# platform_designer_hps_system_hps_0_hps register map
Vendor: default_vendor.com; File version: 0.0
Registers are 32-bit, read-write, reset 0x0 unless marked. A register's access mark holds for its fields unless they carry their own. Offsets are from the block's base; [hi:lo] are bit positions; 'fields as' and 'values as' point back to an identical list.

## l3regs — Registers to control L3 interconnect settings
Base 0xFF800000
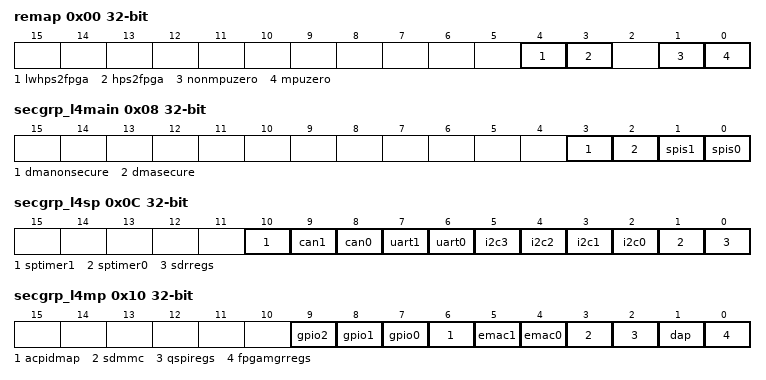
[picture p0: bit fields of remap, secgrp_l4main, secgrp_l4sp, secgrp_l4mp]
0x00 remap wo — The L3 interconnect has separate address maps for the various L3 Masters. Generally, the addresses are the same for most masters. However, the sparse interconnect of the L3 switch causes some masters to have holes in their memory maps. The remap bits are not mutually exclusive. Each bit can be set independently and in combinations. Priority for the bits is determined by the bit offset: lower offset bits take precedence over higher offset bits.
  [4] lwhps2fpga — Controls whether the Lightweight HPS2FPGA AXI Bridge is visible to L3 masters or not.
    0=invisible; 1=visible
  [3] hps2fpga — Controls whether the HPS2FPGA AXI Bridge is visible to L3 masters or not.
    0=invisible; 1=visible
  [1] nonmpuzero — Controls whether address 0x0 for the non-MPU L3 masters is mapped to the SDRAM or On-chip RAM. This field only has an effect on the non-MPU L3 masters. The non-MPU L3 masters are the DMA controllers (standalone and those built-in to peripherals), the FPGA2HPS AXI Bridge, and the DAP.
    0=sdram; 1=ocram
  [0] mpuzero — Controls whether address 0x0 for the MPU L3 master is mapped to the Boot ROM or On-chip RAM. This field only has an effect on the MPU L3 master.
    0=bootrom; 1=ocram
0x08 secgrp_l4main wo — Controls security settings for L4 Main peripherals.
  [all] fields
    0=secure; 1=nonsecure
  [3] dmanonsecure — Controls whether secure or non-secure masters can access the DMA Non-secure slave.
  [2] dmasecure — Controls whether secure or non-secure masters can access the DMA Secure slave.
  [1] spis1 — Controls whether secure or non-secure masters can access the SPI Slave 1 slave.
  [0] spis0 — Controls whether secure or non-secure masters can access the SPI Slave 0 slave.
0x0C secgrp_l4sp wo — Controls security settings for L4 SP peripherals.
  [all] fields
    0=secure; 1=nonsecure
  [10] sptimer1 — Controls whether secure or non-secure masters can access the SP Timer 1 slave.
  [9] can1 — Controls whether secure or non-secure masters can access the CAN 1 slave.
  [8] can0 — Controls whether secure or non-secure masters can access the CAN 0 slave.
  [7] uart1 — Controls whether secure or non-secure masters can access the UART 1 slave.
  [6] uart0 — Controls whether secure or non-secure masters can access the UART 0 slave.
  [5] i2c3 — Controls whether secure or non-secure masters can access the I2C3 (EMAC 1) slave.
  [4] i2c2 — Controls whether secure or non-secure masters can access the I2C2 (EMAC 0) slave.
  [3] i2c1 — Controls whether secure or non-secure masters can access the I2C1 slave.
  [2] i2c0 — Controls whether secure or non-secure masters can access the I2C0 slave.
  [1] sptimer0 — Controls whether secure or non-secure masters can access the SP Timer 0 slave.
  [0] sdrregs — Controls whether secure or non-secure masters can access the SDRAM Registers slave.
0x10 secgrp_l4mp wo — Controls security settings for L4 MP peripherals.
  [all] fields
    0=secure; 1=nonsecure
  [9] gpio2 — Controls whether secure or non-secure masters can access the GPIO 2 slave.
  [8] gpio1 — Controls whether secure or non-secure masters can access the GPIO 1 slave.
  [7] gpio0 — Controls whether secure or non-secure masters can access the GPIO 0 slave.
  [6] acpidmap — Controls whether secure or non-secure masters can access the ACP ID Mapper slave.
  [5] emac1 — Controls whether secure or non-secure masters can access the EMAC 1 slave.
  [4] emac0 — Controls whether secure or non-secure masters can access the EMAC 0 slave.
  [3] sdmmc — Controls whether secure or non-secure masters can access the SDMMC slave.
  [2] qspiregs — Controls whether secure or non-secure masters can access the QSPI Registers slave.
  [1] dap — Controls whether secure or non-secure masters can access the DAP slave.
  [0] fpgamgrregs — Controls whether secure or non-secure masters can access the FPGA Manager Register slave.
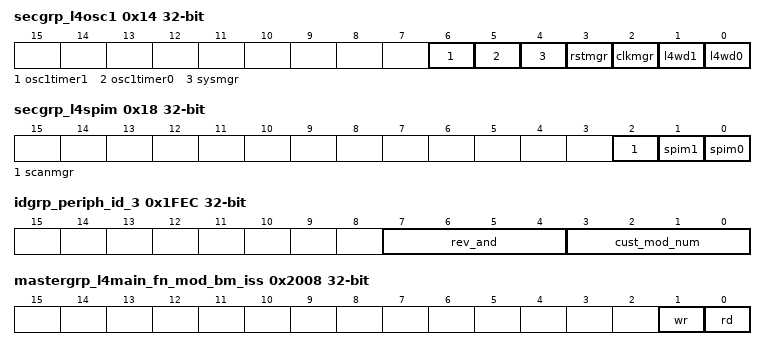
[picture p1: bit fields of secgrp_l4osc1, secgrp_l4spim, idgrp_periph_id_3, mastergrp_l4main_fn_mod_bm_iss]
0x14 secgrp_l4osc1 wo — Controls security settings for L4 OSC1 peripherals.
  [all] fields
    0=secure; 1=nonsecure
  [6] osc1timer1 — Controls whether secure or non-secure masters can access the OSC1 Timer 1 slave.
  [5] osc1timer0 — Controls whether secure or non-secure masters can access the OSC1 Timer 0 slave.
  [4] sysmgr — Controls whether secure or non-secure masters can access the System Manager slave.
  [3] rstmgr — Controls whether secure or non-secure masters can access the Reset Manager slave.
  [2] clkmgr — Controls whether secure or non-secure masters can access the Clock Manager slave.
  [1] l4wd1 — Controls whether secure or non-secure masters can access the L4 Watchdog Timer 0 slave.
  [0] l4wd0 — Controls whether secure or non-secure masters can access the L4 Watchdog Timer 0 slave.
0x18 secgrp_l4spim wo — Controls security settings for L4 SPIM peripherals.
  [all] fields
    0=secure; 1=nonsecure
  [2] scanmgr — Controls whether secure or non-secure masters can access the Scan Manager slave.
  [1] spim1 — Controls whether secure or non-secure masters can access the SPI Master 1 slave.
  [0] spim0 — Controls whether secure or non-secure masters can access the SPI Master 0 slave.
0x1C secgrp_stm wo — Controls security settings for STM peripheral.
  [0] s — Controls whether secure or non-secure masters can access the STM slave.
    0=secure; 1=nonsecure
0x20 secgrp_lwhps2fpgaregs wo — Controls security settings for LWHPS2FPGA AXI Bridge Registers peripheral.
  [0] s — Controls whether secure or non-secure masters can access the LWHPS2FPGA AXI Bridge Registers slave.
    0=secure; 1=nonsecure
0x28 secgrp_usb1 wo — Controls security settings for USB1 Registers peripheral.
  [0] s — Controls whether secure or non-secure masters can access the USB1 Registers slave.
    0=secure; 1=nonsecure
0x2C secgrp_nanddata wo — Controls security settings for NAND Flash Controller Data peripheral.
  [0] s — Controls whether secure or non-secure masters can access the NAND Flash Controller Data slave.
    0=secure; 1=nonsecure
0x80 secgrp_usb0 wo — Controls security settings for USB0 Registers peripheral.
  [0] s — Controls whether secure or non-secure masters can access the USB0 Registers slave.
    0=secure; 1=nonsecure
0x84 secgrp_nandregs wo — Controls security settings for NAND Flash Controller Registers peripheral.
  [0] s — Controls whether secure or non-secure masters can access the NAND Flash Controller Registers slave.
    0=secure; 1=nonsecure
0x88 secgrp_qspidata wo — Controls security settings for QSPI Flash Controller Data peripheral.
  [0] s — Controls whether secure or non-secure masters can access the QSPI Flash Controller Data slave.
    0=secure; 1=nonsecure
0x8C secgrp_fpgamgrdata wo — Controls security settings for FPGA Manager Data peripheral.
  [0] s — Controls whether secure or non-secure masters can access the FPGA Manager Data slave.
    0=secure; 1=nonsecure
0x90 secgrp_hps2fpgaregs wo — Controls security settings for HPS2FPGA AXI Bridge Registers peripheral.
  [0] s — Controls whether secure or non-secure masters can access the HPS2FPGA AXI Bridge Registers slave.
    0=secure; 1=nonsecure
0x94 secgrp_acp wo — Controls security settings for MPU ACP peripheral.
  [0] s — Controls whether secure or non-secure masters can access the MPU ACP slave.
    0=secure; 1=nonsecure
0x98 secgrp_rom wo — Controls security settings for ROM peripheral.
  [0] s — Controls whether secure or non-secure masters can access the ROM slave.
    0=secure; 1=nonsecure
0x9C secgrp_ocram wo — Controls security settings for On-chip RAM peripheral.
  [0] s — Controls whether secure or non-secure masters can access the On-chip RAM slave.
    0=secure; 1=nonsecure
0xA0 secgrp_sdrdata wo — Controls security settings for SDRAM Data peripheral.
  [0] s — Controls whether secure or non-secure masters can access the SDRAM Data slave.
    0=secure; 1=nonsecure
0x1FD0 idgrp_periph_id_4 ro reset 0x4 — JEP106 continuation code
  [7:0] periph_id_4
0x1FE0 idgrp_periph_id_0 ro reset 0x1 — Peripheral ID0
  [7:0] pn7to0 — Part Number [7:0]
0x1FE4 idgrp_periph_id_1 ro reset 0xB3 — Peripheral ID1
  [7:0] jep3to0_pn11to8 — JEP106[3:0], Part Number [11:8]
0x1FE8 idgrp_periph_id_2 ro reset 0x6B — Peripheral ID2
  [7:0] rev_jepcode_jep6to4 — Revision, JEP106 code flag, JEP106[6:4]
0x1FEC idgrp_periph_id_3 ro — Peripheral ID3
  [7:4] rev_and — Revision
  [3:0] cust_mod_num — Customer Model Number
0x1FF0 idgrp_comp_id_0 ro reset 0xD — Component ID0
  [7:0] preamble
0x1FF4 idgrp_comp_id_1 ro reset 0xF0 — Component ID1
  [7:0] genipcompcls_preamble — Generic IP component class, Preamble
0x1FF8 idgrp_comp_id_2 ro reset 0x5 — Component ID2
  [7:0] preamble
0x1FFC idgrp_comp_id_3 ro reset 0xB1 — Component ID3
  [7:0] preamble
0x2008 mastergrp_l4main_fn_mod_bm_iss — Sets the issuing capability of the preceding switch arbitration scheme to multiple or single outstanding transactions.
  [1] wr
    0=multiple; 1=single
  [0] rd
    0=multiple; 1=single
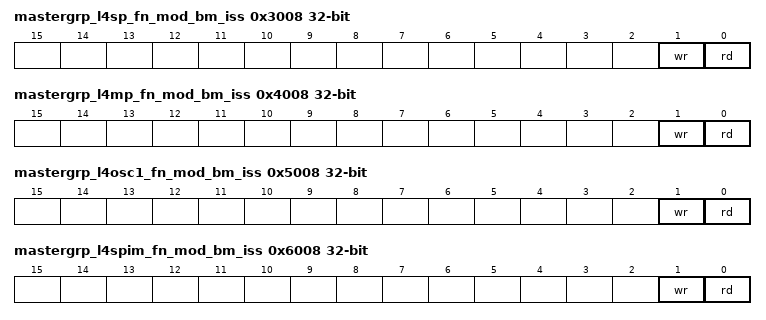
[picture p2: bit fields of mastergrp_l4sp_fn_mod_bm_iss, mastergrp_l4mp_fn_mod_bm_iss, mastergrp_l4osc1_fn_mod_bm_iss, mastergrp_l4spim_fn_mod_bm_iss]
0x3008 mastergrp_l4sp_fn_mod_bm_iss — Sets the issuing capability of the preceding switch arbitration scheme to multiple or single outstanding transactions.
  [1] wr
    0=multiple; 1=single
  [0] rd
    0=multiple; 1=single
0x4008 mastergrp_l4mp_fn_mod_bm_iss — Sets the issuing capability of the preceding switch arbitration scheme to multiple or single outstanding transactions.
  [1] wr
    0=multiple; 1=single
  [0] rd
    0=multiple; 1=single
0x5008 mastergrp_l4osc1_fn_mod_bm_iss — Sets the issuing capability of the preceding switch arbitration scheme to multiple or single outstanding transactions.
  [1] wr
    0=multiple; 1=single
  [0] rd
    0=multiple; 1=single
0x6008 mastergrp_l4spim_fn_mod_bm_iss — Sets the issuing capability of the preceding switch arbitration scheme to multiple or single outstanding transactions.
  [1] wr
    0=multiple; 1=single
  [0] rd
    0=multiple; 1=single
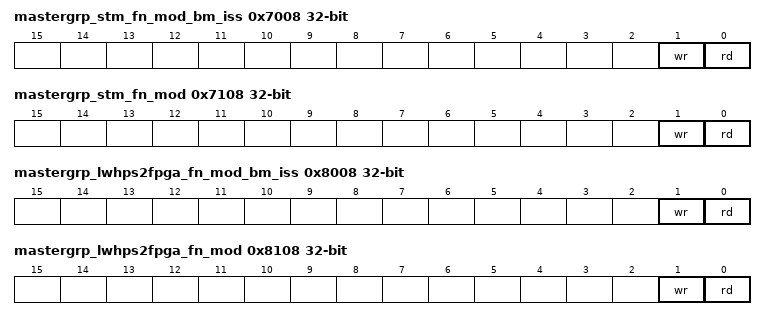
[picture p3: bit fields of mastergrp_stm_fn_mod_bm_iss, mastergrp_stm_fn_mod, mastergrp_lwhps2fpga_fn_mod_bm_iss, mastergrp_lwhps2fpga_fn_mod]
0x7008 mastergrp_stm_fn_mod_bm_iss — Sets the issuing capability of the preceding switch arbitration scheme to multiple or single outstanding transactions.
  [1] wr
    0=multiple; 1=single
  [0] rd
    0=multiple; 1=single
0x7108 mastergrp_stm_fn_mod — Sets the block issuing capability to multiple or single outstanding transactions.
  [1] wr
    0=multiple; 1=single
  [0] rd
    0=multiple; 1=single
0x8008 mastergrp_lwhps2fpga_fn_mod_bm_iss — Sets the issuing capability of the preceding switch arbitration scheme to multiple or single outstanding transactions.
  [1] wr
    0=multiple; 1=single
  [0] rd
    0=multiple; 1=single
0x8108 mastergrp_lwhps2fpga_fn_mod — Sets the block issuing capability to multiple or single outstanding transactions.
  [1] wr
    0=multiple; 1=single
  [0] rd
    0=multiple; 1=single
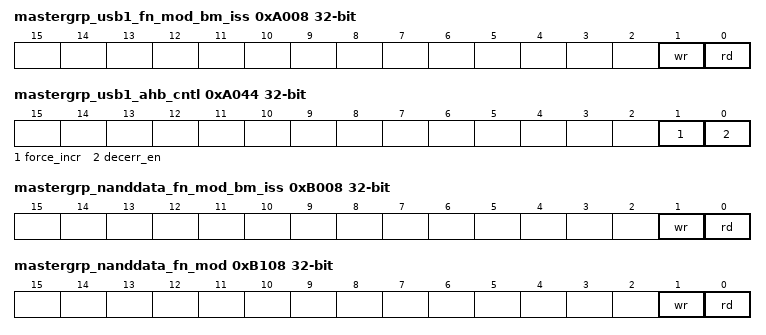
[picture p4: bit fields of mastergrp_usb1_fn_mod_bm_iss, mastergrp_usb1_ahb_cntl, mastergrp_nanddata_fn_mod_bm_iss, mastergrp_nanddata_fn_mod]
0xA008 mastergrp_usb1_fn_mod_bm_iss — Sets the issuing capability of the preceding switch arbitration scheme to multiple or single outstanding transactions.
  [1] wr
    0=multiple; 1=single
  [0] rd
    0=multiple; 1=single
0xA044 mastergrp_usb1_ahb_cntl — Sets the block issuing capability to one outstanding transaction.
  [1] force_incr
    0=disable; 1=enable
  [0] decerr_en
    0=disable; 1=enable
0xB008 mastergrp_nanddata_fn_mod_bm_iss — Sets the issuing capability of the preceding switch arbitration scheme to multiple or single outstanding transactions.
  [1] wr
    0=multiple; 1=single
  [0] rd
    0=multiple; 1=single
0xB108 mastergrp_nanddata_fn_mod — Sets the block issuing capability to multiple or single outstanding transactions.
  [1] wr
    0=multiple; 1=single
  [0] rd
    0=multiple; 1=single
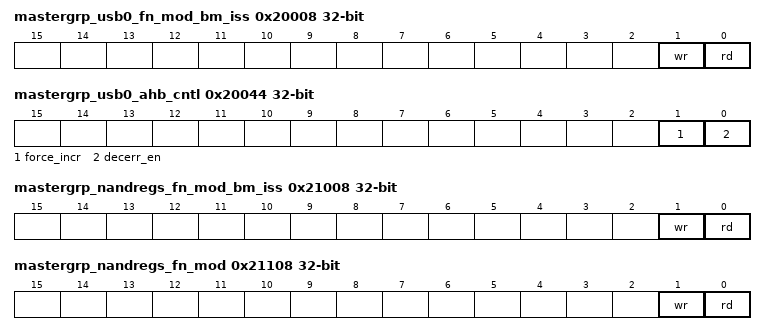
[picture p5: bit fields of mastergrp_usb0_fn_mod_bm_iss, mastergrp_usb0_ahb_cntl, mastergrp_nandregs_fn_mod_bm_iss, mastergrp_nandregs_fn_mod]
0x20008 mastergrp_usb0_fn_mod_bm_iss — Sets the issuing capability of the preceding switch arbitration scheme to multiple or single outstanding transactions.
  [1] wr
    0=multiple; 1=single
  [0] rd
    0=multiple; 1=single
0x20044 mastergrp_usb0_ahb_cntl — Sets the block issuing capability to one outstanding transaction.
  fields as mastergrp_usb1_ahb_cntl
0x21008 mastergrp_nandregs_fn_mod_bm_iss — Sets the issuing capability of the preceding switch arbitration scheme to multiple or single outstanding transactions.
  [1] wr
    0=multiple; 1=single
  [0] rd
    0=multiple; 1=single
0x21108 mastergrp_nandregs_fn_mod — Sets the block issuing capability to multiple or single outstanding transactions.
  [1] wr
    0=multiple; 1=single
  [0] rd
    0=multiple; 1=single
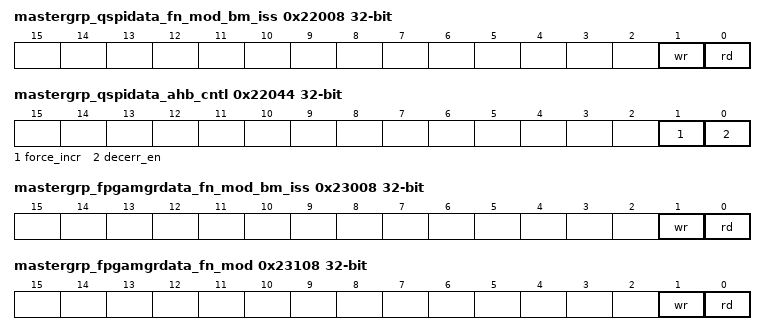
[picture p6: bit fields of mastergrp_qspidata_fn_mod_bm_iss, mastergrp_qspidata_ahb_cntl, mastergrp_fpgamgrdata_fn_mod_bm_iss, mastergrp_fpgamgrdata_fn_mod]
0x22008 mastergrp_qspidata_fn_mod_bm_iss — Sets the issuing capability of the preceding switch arbitration scheme to multiple or single outstanding transactions.
  [1] wr
    0=multiple; 1=single
  [0] rd
    0=multiple; 1=single
0x22044 mastergrp_qspidata_ahb_cntl — Sets the block issuing capability to one outstanding transaction.
  fields as mastergrp_usb1_ahb_cntl
0x23008 mastergrp_fpgamgrdata_fn_mod_bm_iss — Sets the issuing capability of the preceding switch arbitration scheme to multiple or single outstanding transactions.
  [1] wr
    0=multiple; 1=single
  [0] rd
    0=multiple; 1=single
0x23040 mastergrp_fpgamgrdata_wr_tidemark reset 0x4 — Controls the release of the transaction in the write data FIFO.
  [3:0] level — Stalls the transaction in the write data FIFO until the number of occupied slots in the write data FIFO exceeds the level. Note that the transaction is released before this level is achieved if the network receives the WLAST beat or the write FIFO becomes full.
0x23108 mastergrp_fpgamgrdata_fn_mod — Sets the block issuing capability to multiple or single outstanding transactions.
  [1] wr
    0=multiple; 1=single
  [0] rd
    0=multiple; 1=single
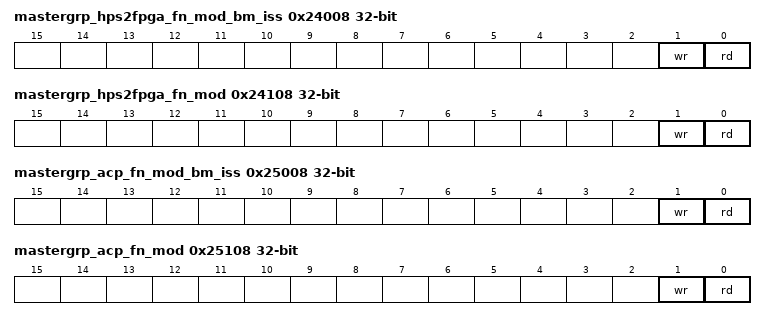
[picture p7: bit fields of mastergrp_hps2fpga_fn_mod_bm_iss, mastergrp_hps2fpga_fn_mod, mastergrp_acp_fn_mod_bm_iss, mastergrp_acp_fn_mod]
0x24008 mastergrp_hps2fpga_fn_mod_bm_iss — Sets the issuing capability of the preceding switch arbitration scheme to multiple or single outstanding transactions.
  [1] wr
    0=multiple; 1=single
  [0] rd
    0=multiple; 1=single
0x24040 mastergrp_hps2fpga_wr_tidemark reset 0x4 — Controls the release of the transaction in the write data FIFO.
  fields as mastergrp_fpgamgrdata_wr_tidemark
0x24108 mastergrp_hps2fpga_fn_mod — Sets the block issuing capability to multiple or single outstanding transactions.
  [1] wr
    0=multiple; 1=single
  [0] rd
    0=multiple; 1=single
0x25008 mastergrp_acp_fn_mod_bm_iss — Sets the issuing capability of the preceding switch arbitration scheme to multiple or single outstanding transactions.
  [1] wr
    0=multiple; 1=single
  [0] rd
    0=multiple; 1=single
0x25108 mastergrp_acp_fn_mod — Sets the block issuing capability to multiple or single outstanding transactions.
  [1] wr
    0=multiple; 1=single
  [0] rd
    0=multiple; 1=single
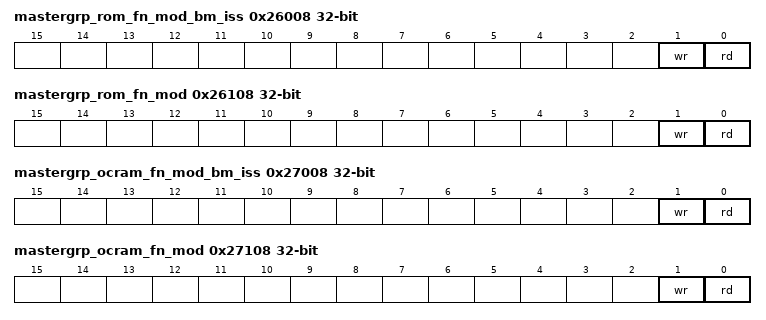
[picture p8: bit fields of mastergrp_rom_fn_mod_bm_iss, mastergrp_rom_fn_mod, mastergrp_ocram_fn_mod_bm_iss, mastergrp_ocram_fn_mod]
0x26008 mastergrp_rom_fn_mod_bm_iss — Sets the issuing capability of the preceding switch arbitration scheme to multiple or single outstanding transactions.
  [1] wr
    0=multiple; 1=single
  [0] rd
    0=multiple; 1=single
0x26108 mastergrp_rom_fn_mod — Sets the block issuing capability to multiple or single outstanding transactions.
  [1] wr
    0=multiple; 1=single
  [0] rd
    0=multiple; 1=single
0x27008 mastergrp_ocram_fn_mod_bm_iss — Sets the issuing capability of the preceding switch arbitration scheme to multiple or single outstanding transactions.
  [1] wr
    0=multiple; 1=single
  [0] rd
    0=multiple; 1=single
0x27040 mastergrp_ocram_wr_tidemark reset 0x4 — Controls the release of the transaction in the write data FIFO.
  fields as mastergrp_fpgamgrdata_wr_tidemark
0x27108 mastergrp_ocram_fn_mod — Sets the block issuing capability to multiple or single outstanding transactions.
  [1] wr
    0=multiple; 1=single
  [0] rd
    0=multiple; 1=single
0x42024 slavegrp_dap_fn_mod2 — Controls bypass merge of upsizing/downsizing.
  [0] bypass_merge
    0=alter; 1=noalter
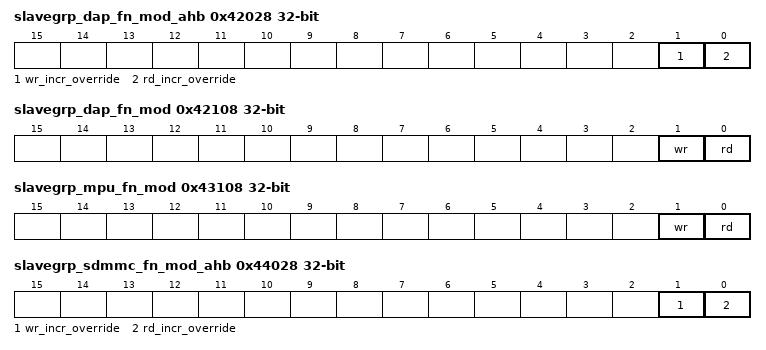
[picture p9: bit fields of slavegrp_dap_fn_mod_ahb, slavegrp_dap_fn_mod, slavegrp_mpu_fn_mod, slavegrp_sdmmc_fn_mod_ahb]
0x42028 slavegrp_dap_fn_mod_ahb — Controls how AHB-lite burst transactions are converted to AXI tranactions.
  [1] wr_incr_override — Controls how AHB-lite write burst transactions are converted to AXI tranactions.
    0=default; 1=singles
  [0] rd_incr_override — Controls how AHB-lite read burst transactions are converted to AXI tranactions.
    0=default; 1=singles
0x42100 slavegrp_dap_read_qos — QoS (Quality of Service) value for the read channel.
  [3:0] pri — QoS (Quality of Service) value for the read channel. A higher value has a higher priority.
0x42104 slavegrp_dap_write_qos — QoS (Quality of Service) value for the write channel.
  [3:0] pri — QoS (Quality of Service) value for the write channel. A higher value has a higher priority.
0x42108 slavegrp_dap_fn_mod — Sets the block issuing capability to multiple or single outstanding transactions.
  [1] wr
    0=multiple; 1=single
  [0] rd
    0=multiple; 1=single
0x43100 slavegrp_mpu_read_qos — QoS (Quality of Service) value for the read channel.
  fields as slavegrp_dap_read_qos
0x43104 slavegrp_mpu_write_qos — QoS (Quality of Service) value for the write channel.
  fields as slavegrp_dap_write_qos
0x43108 slavegrp_mpu_fn_mod — Sets the block issuing capability to multiple or single outstanding transactions.
  [1] wr
    0=multiple; 1=single
  [0] rd
    0=multiple; 1=single
0x44028 slavegrp_sdmmc_fn_mod_ahb — Controls how AHB-lite burst transactions are converted to AXI tranactions.
  fields as slavegrp_dap_fn_mod_ahb
0x44100 slavegrp_sdmmc_read_qos — QoS (Quality of Service) value for the read channel.
  fields as slavegrp_dap_read_qos
0x44104 slavegrp_sdmmc_write_qos — QoS (Quality of Service) value for the write channel.
  fields as slavegrp_dap_write_qos
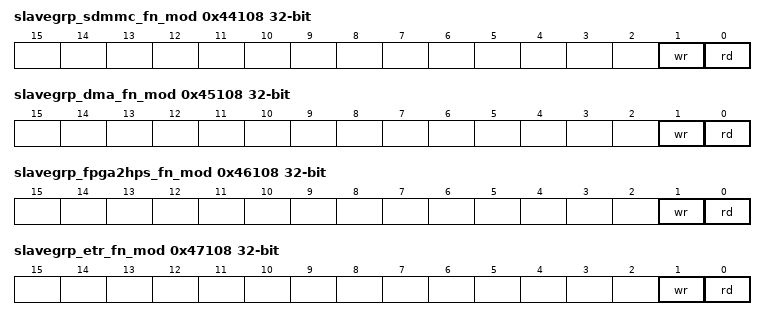
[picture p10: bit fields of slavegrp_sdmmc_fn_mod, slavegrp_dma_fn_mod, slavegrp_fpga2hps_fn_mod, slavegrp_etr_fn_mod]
0x44108 slavegrp_sdmmc_fn_mod — Sets the block issuing capability to multiple or single outstanding transactions.
  [1] wr
    0=multiple; 1=single
  [0] rd
    0=multiple; 1=single
0x45100 slavegrp_dma_read_qos — QoS (Quality of Service) value for the read channel.
  fields as slavegrp_dap_read_qos
0x45104 slavegrp_dma_write_qos — QoS (Quality of Service) value for the write channel.
  fields as slavegrp_dap_write_qos
0x45108 slavegrp_dma_fn_mod — Sets the block issuing capability to multiple or single outstanding transactions.
  [1] wr
    0=multiple; 1=single
  [0] rd
    0=multiple; 1=single
0x46040 slavegrp_fpga2hps_wr_tidemark reset 0x4 — Controls the release of the transaction in the write data FIFO.
  fields as mastergrp_fpgamgrdata_wr_tidemark
0x46100 slavegrp_fpga2hps_read_qos — QoS (Quality of Service) value for the read channel.
  fields as slavegrp_dap_read_qos
0x46104 slavegrp_fpga2hps_write_qos — QoS (Quality of Service) value for the write channel.
  fields as slavegrp_dap_write_qos
0x46108 slavegrp_fpga2hps_fn_mod — Sets the block issuing capability to multiple or single outstanding transactions.
  [1] wr
    0=multiple; 1=single
  [0] rd
    0=multiple; 1=single
0x47100 slavegrp_etr_read_qos — QoS (Quality of Service) value for the read channel.
  fields as slavegrp_dap_read_qos
0x47104 slavegrp_etr_write_qos — QoS (Quality of Service) value for the write channel.
  fields as slavegrp_dap_write_qos
0x47108 slavegrp_etr_fn_mod — Sets the block issuing capability to multiple or single outstanding transactions.
  [1] wr
    0=multiple; 1=single
  [0] rd
    0=multiple; 1=single
0x48100 slavegrp_emac0_read_qos — QoS (Quality of Service) value for the read channel.
  fields as slavegrp_dap_read_qos
0x48104 slavegrp_emac0_write_qos — QoS (Quality of Service) value for the write channel.
  fields as slavegrp_dap_write_qos
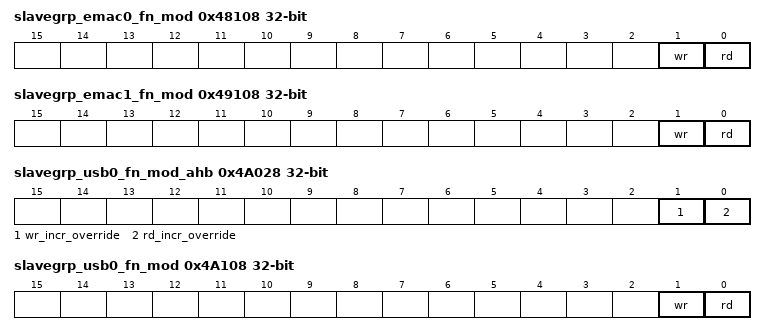
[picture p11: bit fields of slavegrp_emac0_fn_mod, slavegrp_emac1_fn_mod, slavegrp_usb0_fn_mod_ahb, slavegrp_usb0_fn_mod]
0x48108 slavegrp_emac0_fn_mod — Sets the block issuing capability to multiple or single outstanding transactions.
  [1] wr
    0=multiple; 1=single
  [0] rd
    0=multiple; 1=single
0x49100 slavegrp_emac1_read_qos — QoS (Quality of Service) value for the read channel.
  fields as slavegrp_dap_read_qos
0x49104 slavegrp_emac1_write_qos — QoS (Quality of Service) value for the write channel.
  fields as slavegrp_dap_write_qos
0x49108 slavegrp_emac1_fn_mod — Sets the block issuing capability to multiple or single outstanding transactions.
  [1] wr
    0=multiple; 1=single
  [0] rd
    0=multiple; 1=single
0x4A028 slavegrp_usb0_fn_mod_ahb — Controls how AHB-lite burst transactions are converted to AXI tranactions.
  fields as slavegrp_dap_fn_mod_ahb
0x4A100 slavegrp_usb0_read_qos — QoS (Quality of Service) value for the read channel.
  fields as slavegrp_dap_read_qos
0x4A104 slavegrp_usb0_write_qos — QoS (Quality of Service) value for the write channel.
  fields as slavegrp_dap_write_qos
0x4A108 slavegrp_usb0_fn_mod — Sets the block issuing capability to multiple or single outstanding transactions.
  [1] wr
    0=multiple; 1=single
  [0] rd
    0=multiple; 1=single
0x4B100 slavegrp_nand_read_qos — QoS (Quality of Service) value for the read channel.
  fields as slavegrp_dap_read_qos
0x4B104 slavegrp_nand_write_qos — QoS (Quality of Service) value for the write channel.
  fields as slavegrp_dap_write_qos
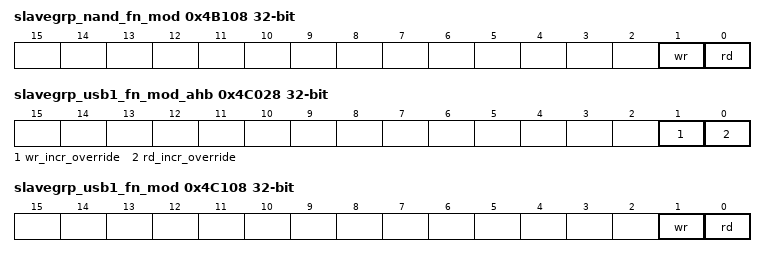
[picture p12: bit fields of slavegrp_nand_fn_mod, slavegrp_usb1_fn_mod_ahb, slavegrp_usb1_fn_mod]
0x4B108 slavegrp_nand_fn_mod — Sets the block issuing capability to multiple or single outstanding transactions.
  [1] wr
    0=multiple; 1=single
  [0] rd
    0=multiple; 1=single
0x4C028 slavegrp_usb1_fn_mod_ahb — Controls how AHB-lite burst transactions are converted to AXI tranactions.
  fields as slavegrp_dap_fn_mod_ahb
0x4C100 slavegrp_usb1_read_qos — QoS (Quality of Service) value for the read channel.
  fields as slavegrp_dap_read_qos
0x4C104 slavegrp_usb1_write_qos — QoS (Quality of Service) value for the write channel.
  fields as slavegrp_dap_write_qos
0x4C108 slavegrp_usb1_fn_mod — Sets the block issuing capability to multiple or single outstanding transactions.
  [1] wr
    0=multiple; 1=single
  [0] rd
    0=multiple; 1=single
